# apollo3p register map
Vendor: Ambiq Micro; Series: Apollo; File version: 1.0
CPU: CM4 r1p0, little endian, MPU, FPU, I-cache, D-cache, VTOR, ITCM, DTCM, 3 interrupt priority bits, 0 interrupts
Registers are 32-bit, read-write, reset 0x0 unless marked. A register's access mark holds for its fields unless they carry their own. Offsets are from the block's base; [hi:lo] are bit positions; {n}, {i} and the like mark numbered series; 'fields as' and 'values as' point back to an identical list.

## MSPI0 — Multi-bit SPI Master
Base 0x50014000
Same registers: MSPI1 0x50015000, MSPI2 0x50016000
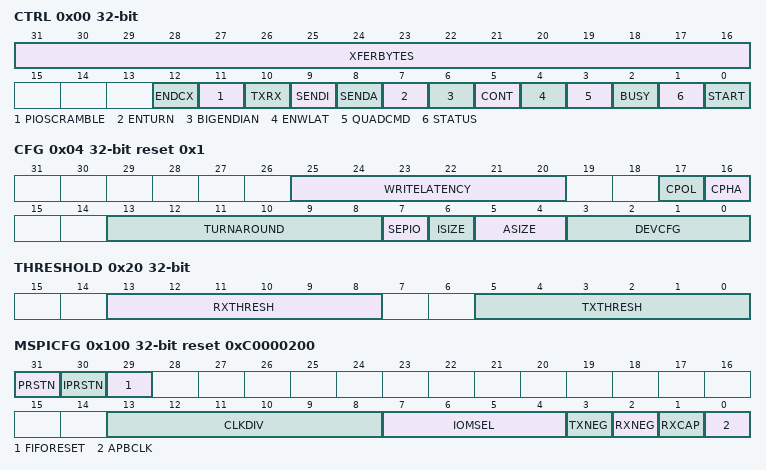
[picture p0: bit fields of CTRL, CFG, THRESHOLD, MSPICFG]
0x00 CTRL — This register is used to enable individual PIO based transactions to a device on the bus. The CFG register must be programmed properly for the transfer, and the ADDR and INSTR registers should be programmed if the SENDI and SENDA fields are enabled.
  [31:16] XFERBYTES — Number of bytes to transmit or receive (based on TXRX bit)
  [12] ENDCX — Enable DCX signal on data [1]
  [11] PIOSCRAMBLE — Enables data scrambling for PIO operations. This should only be used for data operations and never for commands to a device.
  [10] TXRX — 1 Indicates a TX operation, 0 indicates an RX operation of XFERBYTES
  [9] SENDI — Indicates whether an instruction phase should be sent (see INSTR field and ISIZE field in CFG register)
  [8] SENDA — Indicates whether an address phase should be sent (see ADDR register and ASIZE field in CFG register)
  [7] ENTURN — Indicates whether TX->RX turnaround cycles should be enabled for this operation (see TURNAROUND field in CFG register).
  [6] BIGENDIAN — 1 indicates data in FIFO is in big endian format (MSB first); 0 indicates little endian data (default, LSB first).
  [5] CONT — Continuation transfer. When 1, indicates that the MSPI will hold CE low after the transaction completes. This is included for compatibility with IOM module since the MSPI transfer module can handle most cases in a single transfer. NOTE: CONT functionality only works with CLKDIV=2 (24 MHz).
  [4] ENWLAT — Enable Write Latency Counter (time between address and first data byte). Counter value is WRITELATENCY.
  [3] QUADCMD — Flag indicating that the operation is a command that should be replicated to both devices in paired QUAD mode. This is typically only used when reading/writing configuration registers in paired flash devices (do not set for memory transfers).
  [2] BUSY — Command status: 1 indicates controller is busy (command in progress)
  [1] STATUS — Command status: 1 indicates command has completed. Cleared by writing 1 to this bit or starting a new transfer.
  [0] START — Write to 1 to initiate a PIO transaction on the bus (typically the entire register should be written at once with this bit set).
0x04 CFG reset 0x1 — Command formatting for PIO based transactions (initiated by writes to CTRL register)
  [25:20] WRITELATENCY — Number of cycles between addressn and TX data. Qualified by ENLAT
  [17] CPOL — Serial clock polarity.
    0=LOW (Clock inactive state is low.); 1=HIGH (Clock inactive state is high.)
  [16] CPHA — Serial clock phase.
    0=MIDDLE (Clock toggles in middle of data bit.); 1=START (Clock toggles at start of data bit.)
  [13:8] TURNAROUND — Number of turnaround cycles (for TX->RX transitions). Qualified by ENTURN or XIPENTURN bit field.
  [7] SEPIO — Separate IO configuration. This bit should be set when the target device has separate MOSI and MISO pins. Respective IN/OUT bits below should be set to map pins.
  [6] ISIZE — Instruction Size enum name = I8 value = 0x0 desc = Instruction is 1 byte enum name = I16 value = 0x1 desc = Instruction is 2 bytes
  [5:4] ASIZE — Address Size. Address bytes to send from ADDR register
    0=A1 (Send one address byte); 1=A2 (Send two address bytes); 2=A3 (Send three address bytes); 3=A4 (Send four address bytes)
  [3:0] DEVCFG — Flash configuration for XIP and AUTO DMA operations. Controls value for SER (Slave Enable) for XIP operations and address generation for DMA/XIP modes. Also used to configure SPIFRF (frame format).
    1=SERIAL0 (Single bit SPI flash on chip select 0); 2=SERIAL1 (Single bit SPI flash on chip select 1); 5=DUAL0 (Dual SPI flash on chip select 0); 6=DUAL1 (Dual bit SPI flash on chip select 1); 9=QUAD0 (Quad SPI flash on chip select 0); 10=QUAD1 (Quad SPI flash on chip select 1); 13=OCTAL0 (Octal SPI flash on chip select 0); 14=OCTAL1 (Octal SPI flash on chip select 1)
0x08 ADDR — Optional Address field to send for PIO transfers
  [31:0] ADDR — Optional Address field to send (after optional instruction field) - qualified by ASIZE in CMD register. NOTE: This register is aliased to DMADEVADDR.
0x0C INSTR — Optional Instruction field to send for PIO transfers
  [15:0] INSTR — Optional Instruction field to send (1st byte) - qualified by ISEND/ISIZE
0x10 TXFIFO — TX Data FIFO
  [31:0] TXFIFO — Data to be transmitted. Data should normally be aligned to the LSB (pad the upper bits with zeros) unless BIGENDIAN is set.
0x14 RXFIFO — RX Data FIFO
  [31:0] RXFIFO — Receive data. Data is aligned to the LSB (padded zeros on upper bits) unless BIGENDIAN is set.
0x18 TXENTRIES — Number of words in TX FIFO
  [5:0] TXENTRIES — Number of 32-bit words/entries in TX FIFO
0x1C RXENTRIES — Number of words in RX FIFO
  [5:0] RXENTRIES — Number of 32-bit words/entries in RX FIFO
0x20 THRESHOLD — Threshold levels that trigger RXFull and TXEmpty interrupts
  [13:8] RXTHRESH — Number of entries in TX FIFO that cause RXE interrupt
  [5:0] TXTHRESH — Number of entries in TX FIFO that cause TXF interrupt
0x100 MSPICFG reset 0xC0000200 — Timing configuration bits for the MSPI module. PRSTN, IPRSTN, and FIFORESET can be used to reset portions of the MSPI interface in order to clear error conditions. The remaining bits control clock frequency and TX/RX capture timings.
  [31] PRSTN — Peripheral reset. Master reset to the entire MSPI module (DMA, XIP, and transfer state machines). 1=normal operation, 0=in reset.
  [30] IPRSTN — IP block reset. Write to 0 to put the transfer module in reset or 1 for normal operation. This may be required after error conditions to clear the transfer on the bus.
  [29] FIFORESET — Reset MSPI FIFO (active high). 1=reset FIFO, 0=normal operation. May be used to manually flush the FIFO in error handling.
  [13:8] CLKDIV — Clock Divider. Allows dividing 48 MHz base clock by integer multiples. Enumerations are provided for common frequency, but any integer divide from 48 MHz is allowed. Odd divide ratios will result in a 33/66 percent duty cycle with a long low clock pulse (to allow longer round-trip for read data).
    1=CLK48 (48 MHz MSPI clock); 2=CLK24 (24 MHz MSPI clock); 4=CLK12 (12 MHz MSPI clock); 8=CLK6 (6 MHz MSPI clock); 16=CLK3 (3 MHz MSPI clock); 32=CLK1_5 (1.5 MHz MSPI clock)
  [7:4] IOMSEL — Selects which IOM is selected for CQ handshake status.
    {v}=IOM{v} (Select IOM{v}) (v=0..5); 8=MSPI0 (Select MSPI0); 9=MSPI1 (Select MSPI1); 10=MSPI2 (Select MSPI2); 7=DISABLED (No IOM selected. Signals always zero.)
  [3] TXNEG — Launches TX data a half clock cycle (~10 ns) early. This should normally be programmed to zero (NORMAL).
    0=NORMAL (TX launched from posedge internal clock); 1=NEGEDGE (TX data launched from negedge of internal clock)
  [2] RXNEG — Adjusts the RX capture phase to the negedge of the 48MHz internal clock (~10 ns early). For normal operation, it is expected that RXNEG will be set to 0.
    0=NORMAL (RX data sampled on posedge of internal clock); 1=NEGEDGE (RX data sampled on negedge of internal clock)
  [1] RXCAP — Controls RX data capture phase. A setting of 0 (NORMAL) captures read data at the normal capture point relative to the internal clock launch point. However, to accommodate chip/pad/board delays, a setting of RXCAP of 1 is expected to be used to align the capture point with the return data window. This bit is used in conjunction with RXNEG to provide 4 unique capture points, all about 10 ns apart.
    0=NORMAL (RX Capture phase aligns with CPHA setting); 1=DELAY (RX Capture phase is delayed from CPHA setting by one clock edge)
  [0] APBCLK — Enable continuous APB clock. For power-efficient operation, APBCLK should be set to 0.
    0=DIS (Disable continuous clock.); 1=EN (Enable continuous clock.)
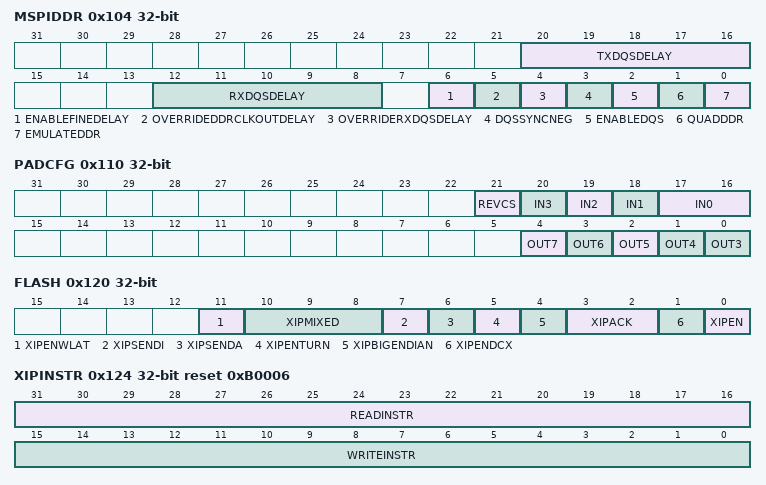
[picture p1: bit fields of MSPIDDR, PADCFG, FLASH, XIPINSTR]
0x104 MSPIDDR — Timing configuration bits for DDR operation of the MSPI module.
  [20:16] TXDQSDELAY — When OVERRIDEDQSDELAY is set this sets the DQS delay line value. In ENABLEDQS mode, this acts as an offset to the computed value (should be set to 0 by default)
  [12:8] RXDQSDELAY — When OVERRIDEDQSDELAY is set this sets the DQS delay line value. In ENABLEDQS mode, this acts as an offset to the computed value (should be set to 0 by default)
  [6] ENABLEFINEDELAY — Enables use of delay line to provide fine control over traditional RX capture clock.
  [5] OVERRIDEDDRCLKOUTDELAY — Override TX delay line with the value in DQSDELAY (for TX clock offset when in QUADDDR mode)
  [4] OVERRIDERXDQSDELAY — Override DQS delay line with the value in DQSDELAY (for RX capture in QUADDDR mode)
  [3] DQSSYNCNEG — Use negative edge of clock for DDR data sync
  [2] ENABLEDQS — In EMULATEDDR mode, enable DQS for read capture
  [1] QUADDDR — Enables use of delay line to provide fine control over traditional RX capture clock.
  [0] EMULATEDDR — Drive external clock at 1/2 rate to emulate DDR mode
0x110 PADCFG — Configuration bits for the MSPI pads. Allows pads associated with the upper quad to be mapped to corresponding bits on the lower quad. Use of Quad0 pins is recommended for optimal timing.
  [21] REVCS — Reverse CS connections. Allows CS1 to be associated with lower data lanes and CS0 to be associated with upper data lines
  [20] IN3 — Data Input pad 3 pin muxing: 0=pad[3] 1=pad[7]
  [19] IN2 — Data Input pad 2 pin muxing: 0=pad[2] 1=pad[6]
  [18] IN1 — Data Input pad 1 pin muxing: 0=pad[1] 1=pad[5]
  [17:16] IN0 — Data Input pad 0 pin muxing: 0=pad[0] 1=pad[4] 2=pad[1] 3=pad[5]
  [n-3] OUT{n} (n=4..7) — Output pad {n} configuration. 0=data[{n}] 1=data[{n-4}]
  [0] OUT3 — Output pad 3 configuration. 0=data[3] 1=CLK
0x114 PADOUTEN — Enable bits for the MSPI output pads. Each active MSPI line should be set to 1 in the OUTEN field below.
  [9:0] OUTEN — Output pad enable configuration. Indicates which pads should be driven. Bits [3:0] are Quad0 data, [7:4] are Quad1 data, and [8] is clock.
    0x10F=QUAD0 (Quad0 (4 data + 1 clock)); 0x1F0=QUAD1 (Quad1 (4 data + 1 clock)); 0x3FF=OCTAL (Octal (8 data + 1 clock)); 0x103=SERIAL0 (Serial (2 data + 1 clock)); 0x130=SERIAL1 (Serial (2 data + 1 clock))
0x118 PADOVEREN — Enables PIO-like pad override control
  [9:0] OVERRIDEEN — Output pad override enable. Bit mask for pad outputs. When set to 1, the values in the OVERRIDE field are driven on the pad (output enable is implicitly set in this mode). [7:0]=data [8]=clock [9]=DM
0x11C PADOVER — Override data value
  [9:0] OVERRIDE — Output pad override value. [7:0]=data [8]=clock [9]=DM
0x120 FLASH — When any SPI flash is configured, this register must be properly programmed before XIP or AUTO DMA operations commence.
  [11] XIPENWLAT — Enable Write Latency counter for XIP write transactions
  [10:8] XIPMIXED — Provides override controls for data operations where instruction, address, and data may transfer in different rates.
    0=NORMAL (Transfers all proceed using the settings in DEVCFG register (everything in the same data rate)); 1=D2 (Data operations proceed in dual data rate); 3=AD2 (Address and Data operations proceed in dual data rate); 5=D4 (Data operations proceed in quad data rate); 7=AD4 (Address and Data operations proceed in quad data rate)
  [7] XIPSENDI — Indicates whether XIP/AUTO DMA operations should send an instruction (see READINSTR field and ISIZE field in CFG)
  [6] XIPSENDA — Indicates whether XIP/AUTO DMA operations should send an an address phase (see DMADEVADDR register and ASIZE field in CFG)
  [5] XIPENTURN — Indicates whether XIP/AUTO DMA operations should enable TX->RX turnaround cycles
  [4] XIPBIGENDIAN — Indicates whether XIP/AUTO DMA data transfers are in big or little endian format
  [3:2] XIPACK — Controls transmission of Micron XIP acknowledge cycles (Micron Flash devices only)
    0=NOACK (No acknowledgment sent. Data IOs are tri-stated the first turnaround cycle); 2=ACK (Positive acknowledgment sent. Data IOs are driven to 0 the first turnaround cycle to acknowledge XIP mode); 3=TERMINATE (Negative acknowledgment sent. Data IOs are driven to 1 the first turnaround cycle to terminate XIP mode. XIPSENDI should be re-enabled for the next transfer)
  [1] XIPENDCX — Enable DCX signal on data [1] for XIP/DMA operations
  [0] XIPEN — Enable the XIP (eXecute In Place) function which effectively enables the address decoding of the MSPI device in the flash/cache address space at address 0x04000000-0x07FFFFFF.
0x124 XIPINSTR reset 0xB0006 — When any SPI flash is configured, this register must be properly programmed before XIP or AUTO DMA operations commence.
  [31:16] READINSTR — Read command sent to flash for DMA/XIP operations
  [15:0] WRITEINSTR — Write command sent for DMA operations
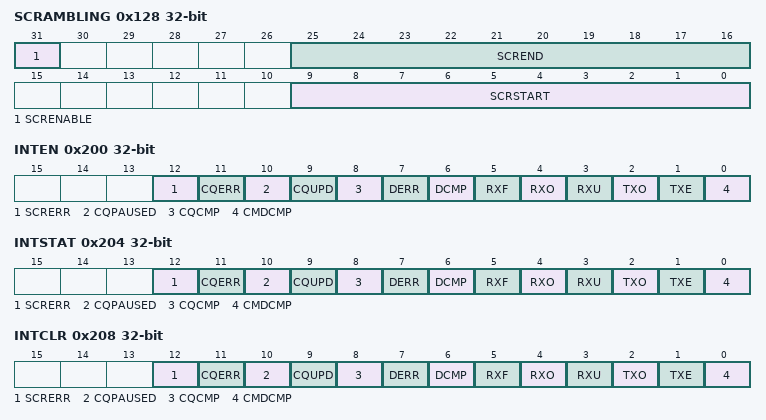
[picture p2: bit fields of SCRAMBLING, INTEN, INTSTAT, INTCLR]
0x128 SCRAMBLING — Enables data scrambling for the specified range external flash addresses. Scrambling does not impact flash access performance.
  [31] SCRENABLE — Enables Data Scrambling Region. When 1 reads and writes to the range will be scrambled. When 0, data will be read/written unmodified. Address range is specified in 64K granularity and the START/END ranges are included within the range.
  [25:16] SCREND — Scrambling region end address [25:16] (64K block granularity). The END block is the LAST block included in the scrambled address range.
  [9:0] SCRSTART — Scrambling region start address [25:16] (64K block granularity). The START block is the FIRST block included in the scrambled address range.
0x200 INTEN — Set bits in this register to allow this module to generate the corresponding interrupt.
  [12] SCRERR — Scrambling Alignment Error. Scrambling operations must be aligned to word (4-byte) start address.
  [11] CQERR — Command Queue Error Interrupt
  [10] CQPAUSED — Command Queue is Paused.
  [9] CQUPD — Command Queue Update Interrupt. Issued whenever the CQ performs an operation where address bit[0] is set. Useful for triggering CURIDX interrupts.
  [8] CQCMP — Command Queue Complete Interrupt
  [7] DERR — DMA Error Interrupt
  [6] DCMP — DMA Complete Interrupt
  [5] RXF — Receive FIFO full
  [4] RXO — Receive FIFO overflow (cannot happen in MSPI design -- MSPI bus pins will stall)
  [3] RXU — Receive FIFO underflow (only occurs when SW reads from an empty FIFO)
  [2] TXO — Transmit FIFO Overflow (only occurs when SW writes to a full FIFO).
  [1] TXE — Transmit FIFO empty.
  [0] CMDCMP — Transfer complete. Note that DMA and CQ operations are layered, so CMDCMP, DCMP, and CQ* can all be signaled simultaneously.
0x204 INTSTAT — Read bits from this register to discover the cause of a recent interrupt.
  fields as INTEN
0x208 INTCLR — Write a 1 to a bit in this register to clear the interrupt status associated with that bit.
  fields as INTEN
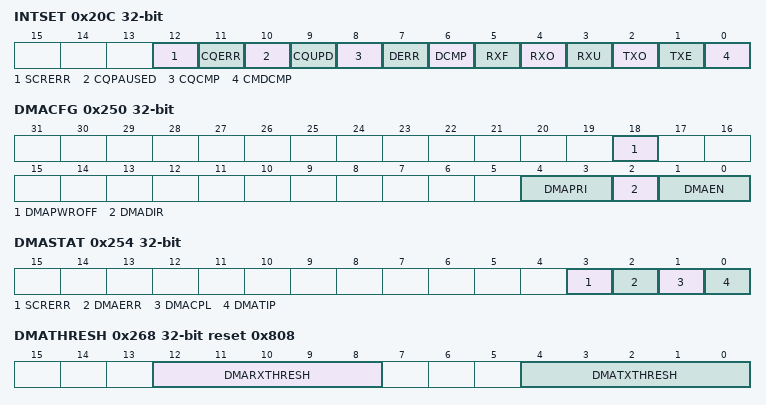
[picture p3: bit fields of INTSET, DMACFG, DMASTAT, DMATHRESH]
0x20C INTSET — Write a 1 to a bit in this register to instantly generate an interrupt from this module. (Generally used for testing purposes).
  fields as INTEN
0x250 DMACFG — DMA Configuration
  [18] DMAPWROFF — Power off MSPI domain upon completion of DMA operation.
  [4:3] DMAPRI — Sets the Priority of the DMA request
    0=LOW (Low Priority (service as best effort)); 1=HIGH (High Priority (service immediately)); 2=AUTO (Auto Priority (priority raised once TX FIFO empties or RX FIFO fills))
  [2] DMADIR — Direction
    0=P2M (Peripheral to Memory (SRAM) transaction); 1=M2P (Memory to Peripheral transaction)
  [1:0] DMAEN — DMA Enable. Setting this bit to EN will start the DMA operation
    0=DIS (Disable DMA Function); 3=EN (Enable HW controlled DMA Function to manage DMA to flash devices. HW will automatically handle issuance of instruction/address bytes based on settings in the FLASH register.)
0x254 DMASTAT — DMA Status
  [3] SCRERR — Scrambling Access Alignment Error. This active high bit signals that a scrambling operation was specified for a non-word aligned DEVADDR.
  [2] DMAERR — DMA Error. This active high bit signals that an error was encountered during the DMA operation.
  [1] DMACPL — DMA Transfer Complete. This signals the end of the DMA operation.
  [0] DMATIP — DMA Transfer In Progress indicator. 1 will indicate that a DMA transfer is active. The DMA transfer may be waiting on data, transferring data, or waiting for priority. All of these will be indicated with a 1. A 0 will indicate that the DMA is fully complete and no further transactions will be done.
0x258 DMATARGADDR — DMA Target Address
  [31:0] TARGADDR — Target byte address for source of DMA (either read or write). In cases of non-word aligned addresses, the DMA logic will take care for ensuring only the target bytes are read/written.
0x25C DMADEVADDR — DMA Device Address
  [31:0] DEVADDR — SPI Device address for automated DMA transactions (both read and write).
0x260 DMATOTCOUNT — DMA Total Transfer Count
  [23:0] TOTCOUNT — Total Transfer Count in bytes.
0x264 DMABCOUNT reset 0x20 — DMA BYTE Transfer Count
  [7:0] BCOUNT — Burst transfer size in bytes. This is the number of bytes transferred when a FIFO trigger event occurs. Recommended value is 32.
0x268 DMATHRESH reset 0x808 — Indicates FIFO level at which a DMA should be triggered. For most configurations, a setting of 8 is recommended for both read and write operations.
  [12:8] DMARXTHRESH — DMA transfer FIFO level trigger. For read operations, DMA is triggered when the FIFO level is greater than this value. For write operations, DMA is triggered when the FIFO level is less than this level. Each DMA operation will consist of BCOUNT bytes.
  [4:0] DMATXTHRESH — DMA transfer FIFO level trigger. For read operations, DMA is triggered when the FIFO level is greater than this value. For write operations, DMA is triggered when the FIFO level is less than this level. Each DMA operation will consist of BCOUNT bytes.
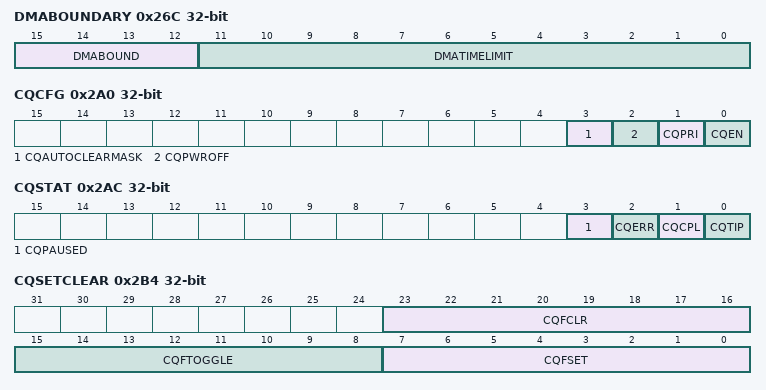
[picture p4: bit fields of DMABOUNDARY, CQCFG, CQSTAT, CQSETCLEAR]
0x26C DMABOUNDARY — Allows large transfers to be broken up into smaller ones in hardware to accommodate needs of external devices and allow XIP/XIPMM. Only applicable for memory-mapped devices (PSRAM, Flash, etc) where address can be retransmitted without side effects.
  [15:12] DMABOUND — DMA Address boundary
    0=NONE (Disable DMA address boundary breaks); 1=BREAK32 (Break at 32 byte boundary (0x20 increments)); 2=BREAK64 (Break at 64 byte boundary (0x40 increments)); 3=BREAK128 (Break at 128 byte boundary (0x80 increments)); 4=BREAK256 (Break at 256 byte boundary (0x100 increments)); 5=BREAK512 (Break at 512 byte boundary (0x200 increments)); 6=BREAK1K (Break at 1KB boundary (0x400 increments)); 7=BREAK2K (Break at 2KB boundary (0x800 increments)); 8=BREAK4K (Break at 4KB boundary (0x1000 increments)); 9=BREAK8K (Break at 8KB boundary (0x2000 increments)); 10=BREAK16K (Break at 16KB boundary (0x4000 increments))
  [11:0] DMATIMELIMIT — DMA time limit. Can be used to limit the transaction time on the MSPI bus. The count is in 100 ns increments. A value of 0 disables the counter.
0x2A0 CQCFG — This register controls Command Queuing (CQ) operations in a manner similar to the DMACFG register.
  [3] CQAUTOCLEARMASK — Enable clear of CQMASK after each pause operation. This may be useful when using software flags to pause CQ.
  [2] CQPWROFF — Power off MSPI domain upon completion of DMA operation.
  [1] CQPRI — Sets the Priority of the command queue DMA request
    0=LOW (Low Priority (service as best effort)); 1=HIGH (High Priority (service immediately))
  [0] CQEN — Command queue enable. When set, will enable the processing of the command queue
    0=DIS (Disable CQ Function); 1=EN (Enable CQ Function)
0x2A8 CQADDR — Location of the command queue in SRAM or flash memory. This register will increment as CQ operations commence. Software should only write CQADDR when CQEN is disabled, however the command queue script itself may update CQADDR in order to perform queue management functions (like resetting the pointers)
  [28:0] CQADDR — Address of command queue buffer in SRAM or flash. The buffer address must be aligned to a word boundary.
0x2AC CQSTAT — Command Queue Status
  [3] CQPAUSED — Command queue is currently paused status.
  [2] CQERR — Command queue processing Error. This active high bit signals that an error was encountered during the CQ operation.
  [1] CQCPL — Command queue operation Complete. This signals the end of the command queue operation.
  [0] CQTIP — Command queue Transfer In Progress indicator. 1 will indicate that a CQ transfer is active and this will remain active even when paused waiting for external event.
0x2B0 CQFLAGS — Command Queue Flags
  [15:0] CQFLAGS — Current flag status (read-only). Bits [7:0] are software controllable and bits [15:8] are hardware status.
    0x8000=STOP (CQ Stop Flag. When set, CQ processing will complete.); 0x4000=CQIDX (CQ Index Pointers (CURIDX/ENDIDX) match.); 0x2000=BUF1XOREN (Buffer 1 Ready Status (from selected IOM/MSPI). This status is the result of XOR'ing the IOM1START with the incoming status from the IOM. When high, MSPI can transfer the buffer.); 0x1000=BUF0XOREN (Buffer 0 Ready Status (from selected IOM/MSPI). This status is the result of XOR'ing the IOM0START with the incoming status from the IOM. When high, MSPI can transfer the buffer.); 0x800=DMACPL (DMA Complete Status (hardwired DMACPL bit in DMASTAT)); 0x400=CMDCPL (PIO Operation completed (STATUS bit in CTRL register)); 0x200=IOM1READY (IOM Buffer 1 Ready Status (from selected IOM). This status is the result of XNOR'ing the IOM0START with the incoming status from the IOM. When high, MSPI can send to the buffer.); 0x100=IOM0READY (IOM Buffer 0 Ready Status (from selected IOM). This status is the result of XNOR'ing the IOM0START with the incoming status from the IOM. When high, MSPI can send to the buffer.); 128=SWFLAG7 (Software flag 7. Can be used by software to start/pause operations.); 64=SWFLAG6 (Software flag 6. Can be used by software to start/pause operations.); 32=SWFLAG5 (Software flag 5. Can be used by software to start/pause operations.); 16=SWFLAG4 (Software flag 4. Can be used by software to start/pause operations.); 8=SWFLAG3 (Software flag 3. Can be used by software to start/pause operations.); 4=SWFLAG2 (Software flag 2. Can be used by software to start/pause operations.); 2=SWFLAG1 (Software flag 1. Can be used by software to start/pause operations.); 1=SWFLAG0 (Software flag 0. Can be used by software to start/pause operations.)
0x2B4 CQSETCLEAR — Command Queue Flag Set/Clear
  [23:16] CQFCLR — Clear CQFlag status bits.
  [15:8] CQFTOGGLE — Toggle CQFlag status bits
  [7:0] CQFSET — Set CQFlag status bits. Set has priority over clear if both are high.
0x2B8 CQPAUSE — Command Queue Pause Mask
  [15:0] CQMASK — CQ will pause processing when ALL specified events are satisfied -- i.e. when (CQMASK and CQPAUSE)==CQMASK.
    values as CQFLAGS.CQFLAGS
0x2C0 CQCURIDX — This register can be used in conjunction with the CQENDIDX register to manage the command queue. Typically software will initialize the CQCURIDX and CQENDIDX to the same value, which will cause the CQ to be paused when enabled. Software may then add entries to the command queue (in SRAM) and update CQENDIDX. The command queue operations will then increment CQCURIDX as it processes operations. Once CQCURIDX==CQENDIDX, the command queue hardware will automatically pause since no additional operations have been appended to the queue.
  [7:0] CQCURIDX — Can be used to indicate the current position of the command queue by having CQ operations write this field. A CQ hardware status flag indicates when CURIDX and ENDIDX are not equal, allowing SW to pause the CQ processing until the end index is updated.
0x2C4 CQENDIDX — Command Queue End Index
  [7:0] CQENDIDX — Can be used to indicate the end position of the command queue. A CQ hardware status bit indices when CURIDX != ENDIDX so that the CQ can be paused when it reaches the end pointer.
